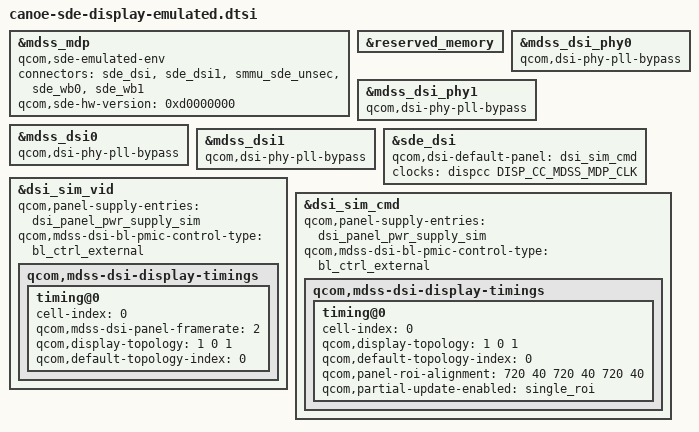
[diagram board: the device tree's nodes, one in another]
// SPDX-License-Identifier: BSD-3-Clause
/*
 * Copyright (c) Qualcomm Technologies, Inc. and/or its subsidiaries.
 */

&mdss_mdp {
	qcom,sde-emulated-env;
	connectors = <&sde_dsi &sde_dsi1 &smmu_sde_unsec &sde_wb0 &sde_wb1>;
	/delete-property/ qcom,sde-has-idle-pc;
	qcom,sde-hw-version = <0xd0000000>;
};

&reserved_memory {
	/delete-node/ splash_memory;
};

&mdss_dsi_phy0 {
	qcom,dsi-phy-pll-bypass;
};

&mdss_dsi_phy1 {
	qcom,dsi-phy-pll-bypass;
};

&mdss_dsi0 {
	qcom,dsi-phy-pll-bypass;
};

&mdss_dsi1 {
	qcom,dsi-phy-pll-bypass;
};

&sde_dsi {
	qcom,dsi-default-panel = <&dsi_sim_cmd>;
	clocks = <&dispcc DISP_CC_MDSS_MDP_CLK>;
	clock-names = "mdp_core_clk";
};

&dsi_sim_vid {
	/delete-property/ qcom,dsi-select-clocks;
	/delete-property/ qcom,mdss-dsi-lane-3-state;
	qcom,panel-supply-entries = <&dsi_panel_pwr_supply_sim>;
	qcom,mdss-dsi-bl-pmic-control-type = "bl_ctrl_external";
	qcom,mdss-dsi-display-timings {
		timing@0 {
			cell-index = <0>;
			qcom,mdss-dsi-panel-framerate = <2>;
			qcom,display-topology = <1 0 1>;
			qcom,default-topology-index = <0>;
			/delete-property/ qcom,compression-mode;
			/delete-property/ qcom,mdss-dsc-slice-height;
			/delete-property/ qcom,mdss-dsc-slice-width;
			/delete-property/ qcom,mdss-dsc-slice-per-pkt;
			/delete-property/ qcom,mdss-dsc-bit-per-component;
			/delete-property/ qcom,mdss-dsc-bit-per-pixel;
			/delete-property/ qcom,mdss-dsc-block-prediction-enable;

		};
	};
};

&dsi_sim_cmd {
	/delete-property/ qcom,dsi-select-clocks;
	/delete-property/ qcom,mdss-dsi-lane-3-state;
	/delete-property/ qcom,poms-align-panel-vsync;
	qcom,panel-supply-entries = <&dsi_panel_pwr_supply_sim>;
	qcom,mdss-dsi-bl-pmic-control-type = "bl_ctrl_external";
	/delete-property/ qcom,ulps-enabled;

	qcom,mdss-dsi-display-timings {
		timing@0 {
			cell-index = <0>;
			qcom,display-topology = <1 0 1>;
			qcom,default-topology-index = <0>;
			/delete-property/ qcom,compression-mode;
			qcom,panel-roi-alignment = <720 40 720 40 720 40>;
			qcom,partial-update-enabled = "single_roi";
		};
	};
};
